# wl_phy_plcp_secure register map
Vendor: Texas Instruments
Peripheral module from a debugger description file (folder CC35X1E).
Registers are 32-bit, read-only, reset 0x0 unless marked. A register's access mark holds for its fields unless they carry their own. Offsets are as the file gives them; lines under a group give offsets from that group; [hi:lo] are bit positions; {n}, {i} and the like mark numbered series; 'fields as' and 'values as' point back to an identical list; <NAME> marks a mode.

## wl_phy_plcp_secure
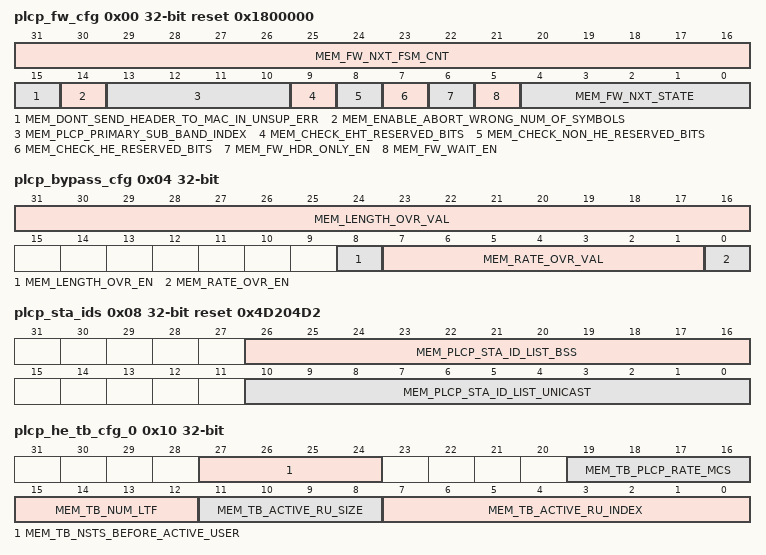
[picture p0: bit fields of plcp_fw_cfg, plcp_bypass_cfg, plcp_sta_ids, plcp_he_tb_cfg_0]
0x00 plcp_fw_cfg rw reset 0x1800000 (reset mask 0xFFFF0000)
  [31:16] MEM_FW_NXT_FSM_CNT — nxt_fsm_cnt in case of FW control in case of error/unsupported packet
  [15] MEM_DONT_SEND_HEADER_TO_MAC_IN_UNSUP_ERR — Don t send header to MAC in case of Unsupported/Error/'Not found our user' packet
  [14] MEM_ENABLE_ABORT_WRONG_NUM_OF_SYMBOLS — Set hdr_err in case plcp_length >2048
  [13:10] MEM_PLCP_PRIMARY_SUB_BAND_INDEX — 0-1 in 40Mhz,0-3 in 80Mhz.which chunk of 20Mhz we need to process
  [9] MEM_CHECK_EHT_RESERVED_BITS — 2 - Check reserved bits on non he packets (Relevant for lsig, VHT SIG, HT SIG)
  [8] MEM_CHECK_NON_HE_RESERVED_BITS — 2 - Check reserved bits on non he packets (Relevant for lsig, VHT SIG, HT SIG)
  [7] MEM_CHECK_HE_RESERVED_BITS — 1 - Check reserved bits on he packets (Relevant for HE_SIGA, HE_SIGB)
  [6] MEM_FW_HDR_ONLY_EN — enable moving into HDR_ONLY_STATE in case of error/unsupported
  [5] MEM_FW_WAIT_EN — enable FW control on state and cnt in case of error/unsup
  [4:0] MEM_FW_NXT_STATE — nxt_state in case of FW control in case of error/unsupported packet
0x04 plcp_bypass_cfg access per field
  [31:16] MEM_LENGTH_OVR_VAL rw — Defined length from FW
  [8] MEM_LENGTH_OVR_EN rw — Enable define length from FW
  [7:1] MEM_RATE_OVR_VAL rw — Defined rate from FW
  [0] MEM_RATE_OVR_EN rw — Enable define rate from FW
0x08 plcp_sta_ids access per field reset 0x4D204D2
  [26:16] MEM_PLCP_STA_ID_LIST_BSS rw — Required id for bss
  [10:0] MEM_PLCP_STA_ID_LIST_UNICAST rw — Required sta id for unicast
0x0C plcp_max_length access per field reset 0xFFFFFFFF
  [15:0] MEM_MAX_PACKET_LENGTH rw — If packet length > reg_value,packets is considered as Error packet
0x10 plcp_he_tb_cfg_0 access per field reset not defined
  [27:24] MEM_TB_NSTS_BEFORE_ACTIVE_USER rw — NSTS before our user in case of receiving supported HE_TB packet
  [19:16] MEM_TB_PLCP_RATE_MCS rw — MCS Rate in case of receiving supported HE_TB packet
  [15:12] MEM_TB_NUM_LTF rw — Num of LTF in case of receiving supported HE_TB packet
  [11:8] MEM_TB_ACTIVE_RU_SIZE rw — Active RU size in case of receiving supported HE_TB packet
  [7:0] MEM_TB_ACTIVE_RU_INDEX rw — Active RU Index in case of receiving supported HE_TB packet
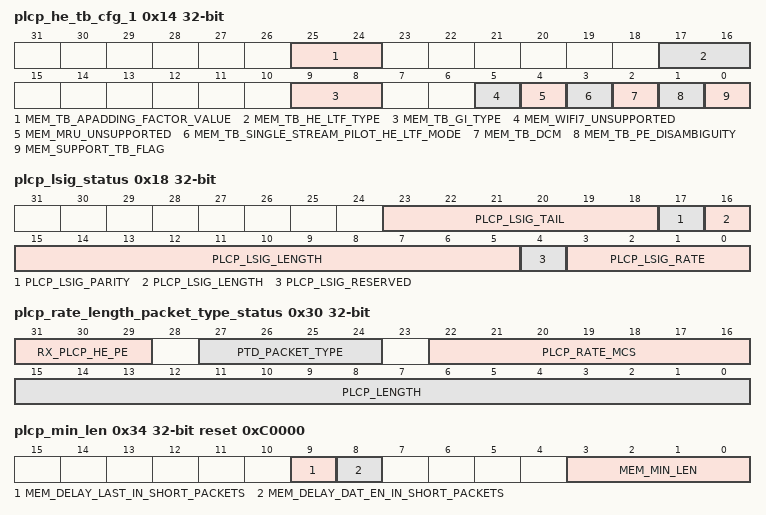
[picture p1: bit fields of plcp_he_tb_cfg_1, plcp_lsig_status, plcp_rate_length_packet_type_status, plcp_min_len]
0x14 plcp_he_tb_cfg_1 access per field reset not defined
  [25:24] MEM_TB_APADDING_FACTOR_VALUE rw
  [17:16] MEM_TB_HE_LTF_TYPE rw — HE_LTF_1 = 2'd0#br#HE_LTF_2 = 2'd1#br#HE_LTF_4 = 2'd2#br#
  [9:8] MEM_TB_GI_TYPE rw — SHORT_GI = 2'd0 REGULAR_GI = 2'd1 DOUBLE_GI = 2'd2 QUAD_GI = 2'd3
  [5] MEM_WIFI7_UNSUPPORTED rw
  [4] MEM_MRU_UNSUPPORTED rw
  [3] MEM_TB_SINGLE_STREAM_PILOT_HE_LTF_MODE rw
  [2] MEM_TB_DCM rw
  [1] MEM_TB_PE_DISAMBIGUITY rw
  [0] MEM_SUPPORT_TB_FLAG rw — Enable receiving HE_TB packets (In default, TB packets are unsupported packets)
0x18 plcp_lsig_status — Lsig bits:#br# 3:0 - rate#br# 4 - Reserved#br#16:5 - Length#br#17 - Parity bit#br# 23:18 - tail#br# 4 : Reserved#br##br##br##br#
  [23:18] PLCP_LSIG_TAIL, [17] PLCP_LSIG_PARITY, [16:5] PLCP_LSIG_LENGTH, [4] PLCP_LSIG_RESERVED, [3:0] PLCP_LSIG_RATE
0x1C plcp_siga_lsb_status — 32 LSBs of HE_SIG_A/HT_SIG/VHT_SIG_A
  [31:0] PLCP_SIGA_LSB
0x20 plcp_siga_msb_status — MSBs of HE_SIG_A/HT_SIG/VHT_SIG_A
  [19:0] PLCP_SIGA_MSB
0x24 plcp_sigb_user_lsb_status — 32 LSBs of HE_SIGB of our USER
  [31:0] PLCP_SIGB_USER_LSB
0x28 plcp_sigb_user_msb_status — MSBs of HE_SIGB of our USER
  [19:0] PLCP_SIGB_USER_MSB
0x2C plcp_sigb_common_status — HE_SIG_B Common bits
  [26:0] PLCP_SIGB_COMMON
0x30 plcp_rate_length_packet_type_status reset not defined
  [31:29] RX_PLCP_HE_PE, [27:24] PTD_PACKET_TYPE, [22:16] PLCP_RATE_MCS, [15:0] PLCP_LENGTH
0x34 plcp_min_len access per field reset 0xC0000 (reset mask 0xFFFFFC00)
  [9] MEM_DELAY_LAST_IN_SHORT_PACKETS rw — MCS Rate in case of receiving supported HE_TB packet
  [8] MEM_DELAY_DAT_EN_IN_SHORT_PACKETS rw — MCS Rate in case of receiving supported HE_TB packet
  [3:0] MEM_MIN_LEN rw — Active RU Index in case of receiving supported HE_TB packet
0x38 plcp_state_status
  [4:0] CURR_STATE
